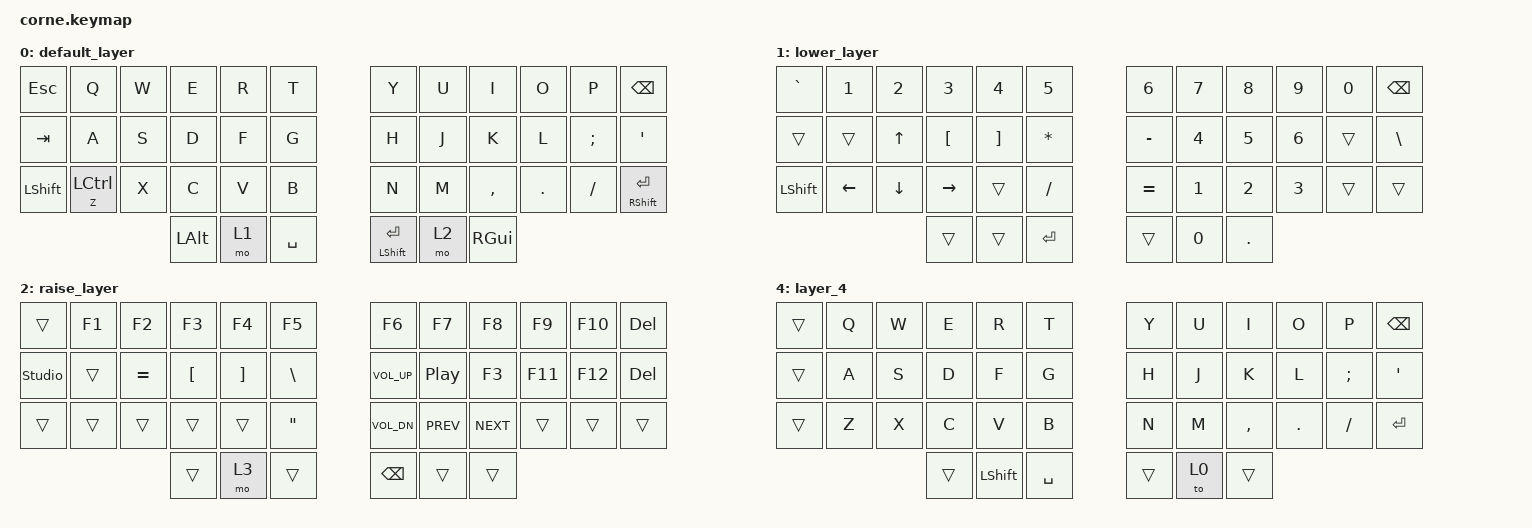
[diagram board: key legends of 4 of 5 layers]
/*
 * Copyright (c) 2020 The ZMK Contributors
 *
 * SPDX-License-Identifier: MIT
 */

#include <behaviors.dtsi>
#include <dt-bindings/zmk/bt.h>
#include <dt-bindings/zmk/keys.h>

/ {
    keymap {
        compatible = "zmk,keymap";

        default_layer {
            // -------------------------------------------------------------------------------------
            // |  ESC |  Q  |  W  |  E  |  R  |  T  |   |  Y  |  U   |  I  |  O  |  P  |   BKSP    |
            // | TAB |  A  |  S  |  D  |  F  |  G  |   |  H  |  J   |  K  |  L  |  ;  |    '      |
            // | SHFT |  CTRL (Z)  |  X  |  C  |  V  |  B  |   |  N  |  M   |  ,  |  .  |  /  | SHFT(RET) |
            //                         | ALT | LWR | SPC | RSE  | GUI |

            bindings = <
&kp ESC    &kp Q        &kp W  &kp E     &kp R  &kp T        &kp Y                 &kp U       &kp I      &kp O    &kp P     &kp BSPC
&kp TAB    &kp A        &kp S  &kp D     &kp F  &kp G        &kp H                 &kp J       &kp K      &kp L    &kp SEMI  &kp SQT
&kp LSHFT  &mt Z LCTRL   &kp X  &kp C     &kp V  &kp B        &kp N                 &kp M       &kp COMMA  &kp DOT  &kp FSLH  &mt RSHFT RET
                               &kp LALT  &mo 1  &kp SPACE    &mt LEFT_SHIFT ENTER  &mo 2  &kp RGUI
            >;
        };

        lower_layer {
            // ----------------------------------------------------------------------------------
            // |  ` |  1 |  2  |  3  |  4  |  5  |   |  6  |  7  |  8 |  9  | 0  |    DEL    |
            // |    |  _  |  +  |  {  |  }  | "|" |   | LFT | DWN |  UP | RGT |  `  |     ~     |
            // |    | ESC | GUI | ALT | CAPS|  "  |   | HOME| END | PGUP| PGDN| PRSC| SHFT(RET) |
            //                       |     |     | RET | ADJ |     |

            bindings = <
&kp GRAVE  &kp N1    &kp N2    &kp N3            &kp N4             &kp N5          &kp N6     &kp N7  &kp N8   &kp N9  &kp N0  &kp BSPC
&trans   &trans    &kp UP    &kp LEFT_BRACKET  &kp RIGHT_BRACKET  &kp ASTERISK    &kp MINUS  &kp N4  &kp N5   &kp N6  &trans  &kp BACKSLASH
&kp LSHFT  &kp LEFT  &kp DOWN  &kp RIGHT         &trans             &kp SLASH       &kp EQUAL  &kp N1  &kp N2   &kp N3  &trans  &trans
                               &trans  &trans   &kp RET         &trans     &kp N0  &kp DOT
            >;
        };

        raise_layer {
            // -----------------------------------------------------------------------------------------
            // |    |  1  |  2  |  3  |  4  |  5  |   |  6  |  7  |  8  |  9  |  0  | DEL |
            // |    |  -  |  =  |  [  |  ]  |  \  |   | F1  | F2  | F3  | F4  | F5  | F6  |
            // |    | ESC | GUI | ALT | CAPS|  "  |   | F7  | F8  | F9  | F10 | F11 | F12 |
            //                       |     | ADJ | BKSP |    |     |

            bindings = <
&trans &kp F1  &kp F2     &kp F3            &kp F4             &kp F5      &kp F6        &kp F7            &kp F8      &kp F9   &kp F10  &kp DEL
&studio_unlock  &trans  &kp EQUAL  &kp LEFT_BRACKET  &kp RIGHT_BRACKET  &kp BSLH    &kp C_VOL_UP  &kp C_PLAY_PAUSE  &kp F3      &kp F11  &kp F12  &kp DEL
&trans  &trans  &trans     &trans            &trans             &kp DQT     &kp C_VOL_DN  &kp C_PREV        &kp C_NEXT  &trans   &trans   &trans
                           &trans  &mo 3   &trans               &kp BSPC    &trans        &trans
            >;
        };

        adjust_layer {
            // -----------------------------------------------------------------------------------------
            // | RGB BRI+ | RGB SAT+ | RGB HUE+ | RGB ANI+ |    | RGB TOG |   |  BT1  | BT2 | BT3 | BT4 | BT5 | BT CLR |
            // | RGB BRI- | RGB SAT- | RGB HUE- | RGB ANI- |    |         |   |       |     |     |     |     |        |
            // |          |          |          |          |    |         |   | RESET |     |     |     |     |        |
            //                                              |     |     |     |     |     |

            bindings = <
&kp A  &none  &none  &none   &none   &none          &bt BT_SEL 0  &bt BT_SEL 1  &bt BT_SEL 2  &bt BT_SEL 3  &bt BT_SEL 4  &bt BT_CLR
&none  &none  &none  &none   &none   &none          &none         &none         &none         &none         &bt BT_NXT    &bt BT_PRV
&none  &none  &none  &none   &none   &bootloader    &bootloader   &none         &none         &none         &none         &bt BT_CLR_ALL
                     &trans  &trans  &tog 3         &trans        &trans
            >;
        };

        layer_4 {
            bindings = <
&trans  &kp Q  &kp W  &kp E   &kp R           &kp T        &kp Y   &kp U  &kp I      &kp O    &kp P     &kp BSPC
&trans  &kp A  &kp S  &kp D   &kp F           &kp G        &kp H   &kp J  &kp K      &kp L    &kp SEMI  &kp SQT
&trans  &kp Z  &kp X  &kp C   &kp V           &kp B        &kp N   &kp M  &kp COMMA  &kp DOT  &kp FSLH  &kp RET
                      &trans  &kp LEFT_SHIFT  &kp SPACE    &trans  &to 0  &trans
            >;
        };
    };
};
